# NAVSS0_PVU_1_IO_PVU1_CFG_MMRS register map
Vendor: Texas Instruments
Peripheral module from a debugger description file (folder J721S2).
Registers are 32-bit, read-only, reset 0x0 unless marked. A register's access mark holds for its fields unless they carry their own. Offsets are as the file gives them; lines under a group give offsets from that group; [hi:lo] are bit positions; {n}, {i} and the like mark numbered series; 'fields as' and 'values as' point back to an identical list; <NAME> marks a mode.

## NAVSS0_PVU_1_IO_PVU1_CFG_MMRS
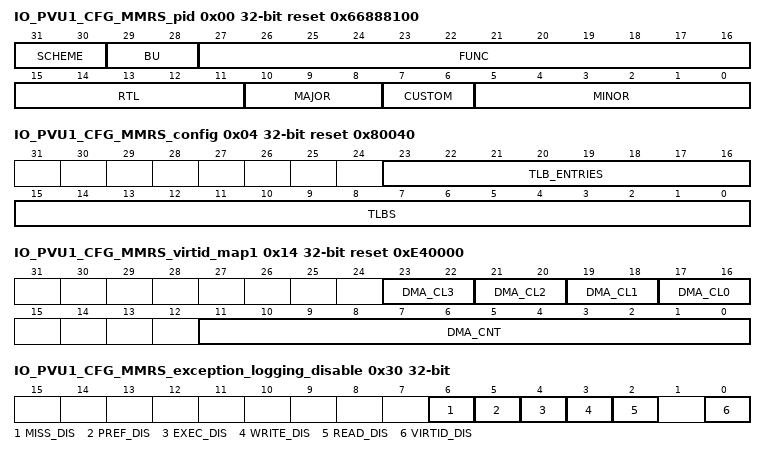
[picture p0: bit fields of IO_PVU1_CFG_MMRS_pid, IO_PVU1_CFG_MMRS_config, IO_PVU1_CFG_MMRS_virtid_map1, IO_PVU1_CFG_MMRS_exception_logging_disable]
0x00 IO_PVU1_CFG_MMRS_pid reset 0x66888100 — The Revision Register contains the major and minor revisions for the module.
  [31:30] SCHEME — PID register scheme
  [29:28] BU — Business Unit: 10 = Processors
  [27:16] FUNC — Module ID
  [15:11] RTL — RTL revision. Will vary depending on release.
  [10:8] MAJOR — Major revision
  [7:6] CUSTOM
  [5:0] MINOR — Minor revision
0x04 IO_PVU1_CFG_MMRS_config reset 0x80040 — The Config Register contains the configuration values for the module.
  [23:16] TLB_ENTRIES — Number of TLB entries per channel
  [15:0] TLBS — Number of TLBs
0x10 IO_PVU1_CFG_MMRS_enable rw — The Enable Register enables the pvu.
  [0] EN — PVU Enable bit. 0 = disabled. 1 = enabled
0x14 IO_PVU1_CFG_MMRS_virtid_map1 rw reset 0xE40000 — The Map Register 1 defines the virtid mapping for the pvu.
  [2n+17:2n+16] DMA_CL{n} (n=0..3) — Map for DMA sub-class {n}. Value is the final sub-class and selects TLB+n.
  [11:0] DMA_CNT — VirtID count for DMA class that use sub-classes.
0x18 IO_PVU1_CFG_MMRS_virtid_map2 rw — The Map Register 2 defines the virtid mapping for the pvu.
  [11:0] MAX_CNT — VirtID maximum for PVU.
0x30 IO_PVU1_CFG_MMRS_exception_logging_disable rw — The Exception Logging Disable Register defines which types of faults are disabled for logging.
  [6] MISS_DIS — Disable for PVU miss fault logging. 0 = enable miss fault logging. 1 = disable miss fault logging.
  [5] PREF_DIS — Disable for prefetch permissions fault logging. 0 = enable prefetch fault logging. 1 = disable prefetch fault logging.
  [4] EXEC_DIS — Disable for execute permissions fault logging. 0 = enable execute fault logging. 1 = disable execute fault logging.
  [3] WRITE_DIS — Disable for write permissions fault logging. 0 = enable write fault logging. 1 = disable write fault logging.
  [2] READ_DIS — Disable for read permissions fault logging. 0 = enable read fault logging. 1 = disable read fault logging.
  [0] VIRTID_DIS — Disable for virtID permission fault logging. 0 = enable virtID fault logging. 1 = disable virtID fault logging.
0x104 IO_PVU1_CFG_MMRS_destination_id rw — The Destination ID Register defines the destination ID value for error messages.
  [7:0] DEST_ID — The destination ID.
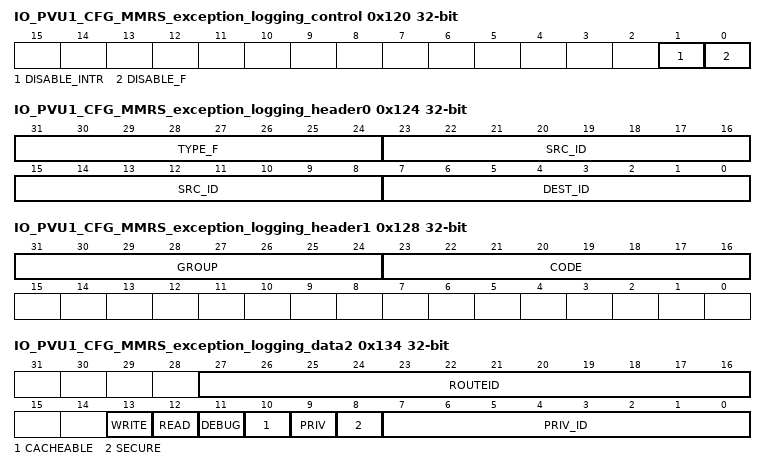
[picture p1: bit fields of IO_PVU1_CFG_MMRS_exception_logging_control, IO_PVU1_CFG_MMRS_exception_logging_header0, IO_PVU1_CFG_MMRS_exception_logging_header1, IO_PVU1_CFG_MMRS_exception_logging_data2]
0x120 IO_PVU1_CFG_MMRS_exception_logging_control rw — The Exception Logging Control Register controls the exception logging.
  [1] DISABLE_INTR — Disables logging interrupt when set. This will not disable logging, so if cleared the current log should also be cleared to guarantee the next log generates the interrupt.
  [0] DISABLE_F — Disables logging when set. This will also disable interrupts.
0x124 IO_PVU1_CFG_MMRS_exception_logging_header0 — The Exception Logging Header 0 Register contains the first word of the header.
  [31:24] TYPE_F — Type. 6 = PVU.
  [23:8] SRC_ID — Source ID.
  [7:0] DEST_ID — Destination ID.
0x128 IO_PVU1_CFG_MMRS_exception_logging_header1 — The Exception Logging Header 1 Register contains the second word of the header.
  [31:24] GROUP
  [23:16] CODE — Code. 0 = PVU miss. 1 = Max virtid violation. 2 = reserved. 3 = read permission violation. 4 = write permission violation. 5 = execute permission violation. 6 = prefetch permission violation.
0x12C IO_PVU1_CFG_MMRS_exception_logging_data0 — The Exception Logging Data 0 Register contains the first word of the data.
  [31:0] ADDR_L — Input virtual address lower 32 bits.
0x130 IO_PVU1_CFG_MMRS_exception_logging_data1 — The Exception Logging Data 1 Register contains the second word of the data.
  [15:0] ADDR_H — Input virtual address upper 12 bits.
0x134 IO_PVU1_CFG_MMRS_exception_logging_data2 — The Exception Logging Data 2 Register contains the third word of the data.
  [27:16] ROUTEID, [13] WRITE, [12] READ, [11] DEBUG, [10] CACHEABLE, [9] PRIV, [8] SECURE, [7:0] PRIV_ID
0x138 IO_PVU1_CFG_MMRS_exception_logging_data3 — The Exception Logging Data 3 Register contains the third word of the data. Reading this register will clear the error pending bit except when emudbg is set.
  [9:0] BYTECNT — Byte count.
0x140 IO_PVU1_CFG_MMRS_exception_pend_set access not given — The Exception Logging Interrupt Pending Set Register allows to set the pend signal.
  [0] PEND_SET — Write a 1 to set the exception pend signal. (access R/W1TS)
0x144 IO_PVU1_CFG_MMRS_exception_pend_clear access not given — The Exception Logging Interrupt Pending Clear Register allows to clear the pend signal.
  [0] PEND_CLR — Write a 1 to clear the exception pend signal. (access R/W1TC)
0x148 IO_PVU1_CFG_MMRS_exception_enable_set access not given — The Exception Logging Interrupt Enable Set Register allows to set the interrupt enable signal.
  [0] ENABLE_SET — Write a 1 to set the exception interrupt enable signal. (access R/W1TS)
0x14C IO_PVU1_CFG_MMRS_exception_enable_clear access not given — The Exception Logging Interrupt Enable Clear Register allows to clear the interrupt enable signal.
  [0] ENABLE_CLR — Write a 1 to clear the exception interrupt enable signal. (access R/W1TC)
0x150 IO_PVU1_CFG_MMRS_eoi_reg rw — EOI Register
  [15:0] EOI_WR
